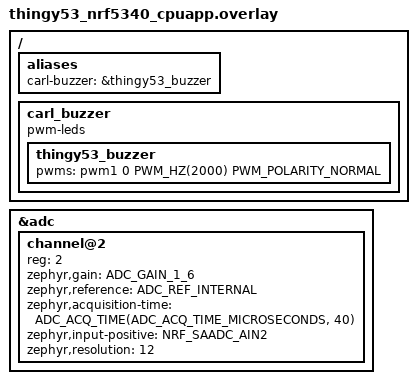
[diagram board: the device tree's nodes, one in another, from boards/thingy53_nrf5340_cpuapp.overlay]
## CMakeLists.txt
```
cmake_minimum_required(VERSION 3.20.0)

find_package(Zephyr REQUIRED HINTS $ENV{ZEPHYR_BASE})

project(carl_node_room LANGUAGES C CXX)

# Per-room environmental sensor node, built around the Nordic Thingy:53.
# Shares the BTHome v2 codec + keystore pattern with the plant-probe node
# (firmware/node-sensor/) so the hub side decodes both with the same path.
# Different sensors_cpp because the onboard chips are different (BME688 +
# BH1749 here vs. BME280 + VEML7700 on the XIAO).
target_sources(app PRIVATE
    src/main.cpp
    src/sensors.cpp
    src/keystore.cpp
    src/bthome_emit.cpp
    src/ui/led.cpp
    src/ui/buzzer.cpp
    # Shared BTHome codec — compiled into the app build, identical to how
    # node-sensor pulls it in.
    ../common/bthome/bthome.cpp
    ../common/bthome/bthome_decode.cpp
    ../common/bthome/aes_ccm.cpp
)

target_include_directories(app PRIVATE
    src
    ../common
    ../common/bthome
)
```

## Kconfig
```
source "Kconfig.zephyr"

menu "Project-Carl room node"

config CARL_ROOM_SAMPLE_INTERVAL_SEC
    int "Sample + broadcast interval (s)"
    default 30
    range 10 600
    help
        How often the room node samples its sensors and emits a BTHome
        advertisement. Default 30 s is bring-up-friendly; production rooms
        with stable conditions can extend this to 5–10 minutes. T/H/P/lux
        change on minute timescales so faster cadence is wasteful.

config CARL_ROOM_BATTERY_LOW_PCT
    int "Battery-low RGB warning threshold (%)"
    default 15
    range 0 100
    help
        Below this level, a successful broadcast blinks amber instead of
        green so a glance at the node signals "needs a charge" without
        checking the dashboard. Matches the hub's default battery_low_pct
        calibration value for consistency.

endmenu
```

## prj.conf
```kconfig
# Carl room-node firmware on the Nordic Thingy:53.
#
# Mirrors firmware/node-sensor/prj.conf wherever it can (BT broadcaster,
# settings/NVS, mbedtls) so the hub decodes both nodes with the same code
# path. Where it differs: enables the Thingy:53's onboard BME688 + BH1749
# sensors, and skips the BME280 / VEML7700 drivers used by the XIAO probe.

# --- Bluetooth (broadcaster only — never connects, just emits BTHome ads) ---
CONFIG_BT=y
CONFIG_BT_PERIPHERAL=y
CONFIG_BT_BROADCASTER=y
CONFIG_BT_DEVICE_NAME="carl-room"
CONFIG_BT_DEVICE_NAME_DYNAMIC=y

# --- Sensors ---
CONFIG_I2C=y
CONFIG_ADC=y
CONFIG_GPIO=y
CONFIG_SENSOR=y
CONFIG_BME680=y          # Zephyr's bme680 driver covers the BME688 part on Thingy:53
CONFIG_BH1749=y          # NCS driver for the Rohm BH1749 RGB/ambient light sensor

# --- Persistence (AES key + counter via settings_nvs) ---
CONFIG_FLASH=y
CONFIG_FLASH_PAGE_LAYOUT=y
CONFIG_FLASH_MAP=y
CONFIG_NVS=y
CONFIG_SETTINGS=y
CONFIG_SETTINGS_NVS=y

# --- RNG for AES key generation on first boot ---
CONFIG_ENTROPY_GENERATOR=y

# --- mbedtls (AES-CCM-128 for BTHome encryption) ---
CONFIG_MBEDTLS=y
CONFIG_MBEDTLS_BUILTIN=y
CONFIG_MBEDTLS_ENABLE_HEAP=y
CONFIG_MBEDTLS_HEAP_SIZE=4096
CONFIG_MBEDTLS_CIPHER_AES_ENABLED=y
CONFIG_MBEDTLS_CIPHER_CCM_ENABLED=y

# --- C++17 to match the shared firmware/common headers ---
CONFIG_CPP=y
CONFIG_STD_CPP17=y
CONFIG_CPP_MAIN=y
CONFIG_LIB_CPLUSPLUS=y
CONFIG_GLIBCXX_LIBCPP=y
CONFIG_NEWLIB_LIBC=y
CONFIG_NEWLIB_LIBC_FLOAT_PRINTF=y

# --- PWM (buzzer on pwm1 + RGB LED on pwm0) ---
CONFIG_PWM=y

# --- Float support for printk (BME688 / BH1749 readings) ---
CONFIG_CBPRINTF_FP_SUPPORT=y

# --- Logging (off by default to save power; flip to y temporarily with
# CONFIG_BT_LOG_LEVEL_DBG=y to diagnose BT host issues during bring-up.) ---
CONFIG_LOG=n
CONFIG_PRINTK=y
```

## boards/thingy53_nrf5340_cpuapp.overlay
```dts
/* Devicetree overlay for the Thingy:53 room node.
 *
 * The board DTS already defines the RGB LED (pwm0 channels 0-2), the buzzer
 * PWM peripheral (pwm1 on P1.15), and a `vbatt` voltage-divider node for the
 * onboard Li-Po (io-channels = <&adc 2>, 1.5M/180k, power-gpios P0.16). This
 * overlay adds:
 *   - the buzzer-as-pwm-led node (grabbed via DT_ALIAS in firmware), and
 *   - the SAADC channel@2 config the vbatt divider needs (the board declares
 *     the divider but not the channel). Channel reg 2 → AIN2 (P0.06), matching
 *     Nordic's `<&adc 2>` reference. The divided Li-Po sits well under the
 *     gain-1/6 / 0.6V-ref full-scale; the 40us acquisition covers the high
 *     divider source impedance.
 */

#include <zephyr/dt-bindings/adc/adc.h>
#include <zephyr/dt-bindings/adc/nrf-adc.h>

/ {
    aliases {
        carl-buzzer = &thingy53_buzzer;
    };

    carl_buzzer: carl_buzzer {
        compatible = "pwm-leds";
        thingy53_buzzer: thingy53_buzzer {
            pwms = <&pwm1 0 PWM_HZ(2000) PWM_POLARITY_NORMAL>;
        };
    };
};

&adc {
    #address-cells = <1>;
    #size-cells = <0>;
    status = "okay";

    channel@2 {
        reg = <2>;
        zephyr,gain = "ADC_GAIN_1_6";
        zephyr,reference = "ADC_REF_INTERNAL";
        zephyr,acquisition-time = <ADC_ACQ_TIME(ADC_ACQ_TIME_MICROSECONDS, 40)>;
        zephyr,input-positive = <NRF_SAADC_AIN2>;
        zephyr,resolution = <12>;
    };
};
```

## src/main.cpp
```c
// Project-Carl — room-monitor node entry point on the Nordic Thingy:53.
//
// Broadcasts T/H/P/lux/battery via BTHome v2 every CARL_ROOM_SAMPLE_INTERVAL_SEC
// seconds. One per room — the hub joins each plant probe's soil reading with
// the room's environment when serving /api/nodes (#16 in the roadmap).
//
// Boot sequence:
//   1. Init sensors + keystore + BT
//   2. Nokia chime on the piezo buzzer + rainbow LED sweep (combined)
//   3. Print MAC + AES key to USB CDC console
//   4. Green LED flash on every successful broadcast, red on failure

#include <zephyr/bluetooth/bluetooth.h>
#include <zephyr/kernel.h>
#include <zephyr/settings/settings.h>
#include <zephyr/sys/printk.h>

#include "bthome_emit.h"
#include "keystore.h"
#include "sensors.h"
#include "ui/buzzer.h"
#include "ui/led.h"

#ifndef CONFIG_CARL_ROOM_SAMPLE_INTERVAL_SEC
#define CONFIG_CARL_ROOM_SAMPLE_INTERVAL_SEC 30
#endif
#ifndef CONFIG_CARL_ROOM_BATTERY_LOW_PCT
#define CONFIG_CARL_ROOM_BATTERY_LOW_PCT 15
#endif

namespace {

const char* airQualityStr(carl::room::sensors::AirQuality aq) {
    using AQ = carl::room::sensors::AirQuality;
    switch (aq) {
        case AQ::kGood:     return "good";
        case AQ::kModerate: return "moderate";
        case AQ::kPoor:     return "poor";
        default:            return "unknown";
    }
}

// Combined boot animation: Nokia tune + rainbow LED sweep.
// Each note of the 13-note tune gets a different colour from the spectrum.
void bootLightShow() {
    struct Step { uint16_t hz; uint16_t ms; uint8_t r, g, b; };
    static constexpr Step kSteps[] = {
        {659, 130, 255,   0,   0},  // E5  — Red
        {587, 130, 255, 100,   0},  // D5  — Orange
        {370, 260, 255, 255,   0},  // F#4 — Yellow
        {415, 260,   0, 255,   0},  // G#4 — Green
        {554, 130,   0, 255, 128},  // C#5 — Spring
        {494, 130,   0, 255, 255},  // B4  — Cyan
        {294, 260,   0, 128, 255},  // D4  — Azure
        {330, 260,   0,   0, 255},  // E4  — Blue
        {494, 130, 128,   0, 255},  // B4  — Violet
        {440, 130, 255,   0, 255},  // A4  — Magenta
        {554, 260, 255,   0, 128},  // C#5 — Rose
        {659, 260, 255, 200, 200},  // E5  — Salmon
        {440, 520, 255, 255, 255},  // A4  — White (finale)
    };

    for (const auto& s : kSteps) {
        carl::room::ui::led::setRGB(s.r, s.g, s.b);
        carl::room::ui::buzzer::tone(s.hz, s.ms);
        k_msleep(20);  // note articulation gap
    }
    carl::room::ui::led::off();
}

void printCredentials() {
    // Always print MAC (not secret). Always print key during bring-up so
    // the user can grab it after any reset — not just first boot. Gate
    // behind a Kconfig flag when shipping production builds.
    bt_addr_le_t addr{};
    size_t addr_count = 1;
    bt_id_get(&addr, &addr_count);
    if (addr_count == 1) {
        const auto* m = addr.a.val;
        printk("\n============================================\n");
        printk("room: MAC  %02X:%02X:%02X:%02X:%02X:%02X\n",
               m[5], m[4], m[3], m[2], m[1], m[0]);
    }
    char hex[33];
    carl::keystore::keyHex(hex);
    printk("room: KEY  %s\n", hex);
    printk("============================================\n\n");
}

void boot() {
    settings_subsys_init();
    settings_load();

    // --- Sensors ---
    if (!carl::room::sensors::init()) {
        printk("room: no sensors initialised — broadcasts will only carry battery\n");
    }

    // --- Keystore ---
    if (!carl::keystore::init()) {
        printk("room: keystore_init failed\n");
    }

    // --- UI ---
    carl::room::ui::led::init();
    carl::room::ui::buzzer::init();

    // --- Bluetooth ---
    if (bt_enable(nullptr) != 0) {
        printk("room: bt_enable failed\n");
        carl::room::ui::buzzer::errorBeep();
        carl::room::ui::led::flashRed(500);
    }
    carl::room::bthome_emit::init();

    // --- Boot animation: Nokia chime + rainbow LED ---
    bootLightShow();

    // --- Credentials (always printed during bring-up) ---
    printCredentials();
}

}  // namespace

int main(void) {
    boot();

    uint32_t sample_no = 0;
    while (true) {
        carl::room::sensors::Sample s{};
        carl::room::sensors::sample(&s);

        printk("room sample #%u: T=%.1fC H=%.0f%% P=%.1fhPa lux=%.0f "
               "gas=%uohm(%s) bat=%u%% (%umV)\n",
               static_cast<unsigned>(sample_no),
               s.temp_ok      ? static_cast<double>(s.temperature_c)   : 0.0,
               s.humidity_ok  ? static_cast<double>(s.humidity_pct)    : 0.0,
               s.pressure_ok  ? static_cast<double>(s.pressure_hpa)   : 0.0,
               s.lux_ok       ? static_cast<double>(s.illuminance_lux) : 0.0,
               static_cast<unsigned>(s.gas_resistance_ohm),
               airQualityStr(s.air_quality),
               static_cast<unsigned>(s.battery_pct),
               static_cast<unsigned>(carl::room::sensors::batteryMv()));

        if (carl::room::bthome_emit::broadcastOnce(s)) {
            // Layer status alerts onto the success blink so a glance at the
            // node signals "needs attention" without checking the dashboard.
            // Poor air takes priority (rarer, more actionable); battery-low
            // is the common case; otherwise plain green — same idea as the
            // plant node's severity blink.
            using AQ = carl::room::sensors::AirQuality;
            const bool battery_low = s.battery_pct > 0
                                    && s.battery_pct <= CONFIG_CARL_ROOM_BATTERY_LOW_PCT;
            if (s.air_quality == AQ::kPoor) {
                carl::room::ui::led::blinkStatus(140, 0, 200, 2);  // 2x purple — poor air
            } else if (battery_low) {
                carl::room::ui::led::blinkStatus(255, 140, 0, 1);  // 1x amber — battery low
            } else {
                carl::room::ui::led::flashGreen();  // all clear
            }
        } else {
            printk("room: broadcast failed\n");
            carl::room::ui::led::flashRed();     // error — red flash
            carl::room::ui::buzzer::errorBeep();
        }

        ++sample_no;
        k_sleep(K_SECONDS(CONFIG_CARL_ROOM_SAMPLE_INTERVAL_SEC));
    }
    return 0;
}
```

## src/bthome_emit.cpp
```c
#include "bthome_emit.h"

#include <cstring>

#include <zephyr/bluetooth/addr.h>
#include <zephyr/bluetooth/bluetooth.h>
#include <zephyr/kernel.h>
#include <zephyr/sys/printk.h>

#include "bthome.h"
#include "keystore.h"

namespace carl::room::bthome_emit {

namespace {

uint8_t g_mac_le[6] = {0};

// How long to broadcast each cycle. Long enough that the hub's passive scan
// (default ~11.25 ms / 11.25 ms = 100 % duty) catches it many times over.
constexpr int kBroadcastMs = 200;

void readMacLe() {
    bt_addr_le_t addr{};
    size_t count = 1;
    bt_id_get(&addr, &count);
    if (count == 1) std::memcpy(g_mac_le, addr.a.val, 6);
}

}  // namespace

bool init() {
    // bt_enable() is called from main; we can read identity here.
    readMacLe();
    return true;
}

bool broadcastOnce(const carl::room::sensors::Sample& s) {
    carl::bthome::Builder b;
    b.addPacketId(static_cast<uint8_t>(carl::keystore::nextCounter() & 0xFF));
    b.addBattery(s.battery_pct);

    if (s.temp_ok)     b.addTemperature(s.temperature_c);
    if (s.humidity_ok) b.addHumidity(s.humidity_pct);
    if (s.pressure_ok) b.addPressure(s.pressure_hpa);
    if (s.lux_ok)      b.addIlluminance(s.illuminance_lux);

    if (!b.ok()) return false;

    uint8_t svc[carl::bthome::kMaxPlaintext + 11];
    size_t  svc_len = 0;
    if (!b.buildEncrypted(svc, sizeof(svc), &svc_len,
                          carl::keystore::key(), g_mac_le,
                          carl::keystore::nextCounter())) {
        return false;
    }

    // BTHome v2 service data only — no BT_DATA_FLAGS. NCS's legacy-adv path
    // rejects the flags-plus-svc-data pair with -EINVAL, and BTHome scanners
    // only key off the service-data UUID 0xFCD2. See firmware/node-sensor/
    // src/bthome_emit.cpp for the long story behind this.
    const struct bt_data ad[] = {
        BT_DATA(BT_DATA_SVC_DATA16, svc, svc_len),
    };

    // BT_LE_ADV_OPT_USE_IDENTITY is required because we don't enable
    // CONFIG_BT_PRIVACY — without it Zephyr can't generate the RPA it
    // would otherwise want to advertise with and bt_le_adv_start returns
    // -EINVAL on every call. Using the device's static random identity
    // address is what we want anyway: stable across reboots so the hub's
    // MAC↔key map keeps working.
    struct bt_le_adv_param param = BT_LE_ADV_PARAM_INIT(
        BT_LE_ADV_OPT_USE_IDENTITY,
        BT_GAP_ADV_FAST_INT_MIN_2,
        BT_GAP_ADV_FAST_INT_MAX_2,
        /*peer=*/nullptr);
    int rc = bt_le_adv_start(&param, ad, ARRAY_SIZE(ad), nullptr, 0);
    if (rc != 0) {
        printk("bt_le_adv_start failed: %d\n", rc);
        return false;
    }
    k_msleep(kBroadcastMs);
    bt_le_adv_stop();
    return true;
}

}  // namespace carl::room::bthome_emit
```

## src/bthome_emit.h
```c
// Build + transmit one BTHome v2 advertisement per sample cycle.
//
// Room node ad fits in a single legacy-AD cycle:
//   packet_id + battery + T + H + P + lux = 18 bytes plaintext
//   + 11 bytes encryption overhead = 29 bytes service data
//   + 2 bytes AD struct header (length + type) = 31 bytes total — at the
//   legacy non-connectable AD ceiling. Adding gas/VOC would require either
//   two-cycle rotation (like firmware/node-sensor/) or extended advertising.

#pragma once

#include "sensors.h"

namespace carl::room::bthome_emit {

bool init();

// Encode one BTHome v2 advertisement and broadcast it for ~200 ms.
// Returns true on success; on failure, prints why to the console.
bool broadcastOnce(const carl::room::sensors::Sample& s);

}  // namespace carl::room::bthome_emit
```

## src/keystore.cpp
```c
#include "keystore.h"

#include <cstring>

#include <zephyr/kernel.h>
#include <zephyr/random/random.h>
#include <zephyr/settings/settings.h>
#include <zephyr/sys/printk.h>

namespace carl::keystore {

namespace {

// Each major settings handler gets its OWN root subtree so Zephyr's
// settings_parse_and_lookup() can route entries unambiguously.
// (When multiple handlers share a root, only the first-linked one gets
// invoked — every other handler's data silently fails to load. That
// regenerated the AES key on every reset before the split.)
constexpr const char* kKeyPath     = "carl_keys/key";
constexpr const char* kCounterPath = "carl_keys/counter";

// Persist the counter to flash every N broadcasts. Lower wears flash faster;
// higher means more counters get re-used after an unclean reset (which is
// safe — the hub rejects non-increasing counters, so a node will simply skip
// ahead by the checkpoint window after reboot).
constexpr uint32_t kCounterCheckpointEvery = 64;

uint8_t   g_key[16];
bool      g_have_key = false;
bool      g_fresh    = false;
uint32_t  g_counter  = 0;
uint32_t  g_counter_persisted = 0;

int settingsLoadCb(const char* name, size_t len, settings_read_cb read_cb,
                   void* cb_arg) {
    const char* next = nullptr;
    int name_len = settings_name_next(name, &next);

    if (name_len == 3 && std::strncmp(name, "key", 3) == 0 && len == sizeof(g_key)) {
        if (read_cb(cb_arg, g_key, sizeof(g_key)) == sizeof(g_key)) {
            g_have_key = true;
        }
        return 0;
    }
    if (name_len == 7 && std::strncmp(name, "counter", 7) == 0
        && len == sizeof(g_counter)) {
        read_cb(cb_arg, &g_counter_persisted, sizeof(g_counter_persisted));
        // Skip ahead a checkpoint window so we never reuse a counter after an
        // unclean reset.
        g_counter = g_counter_persisted + kCounterCheckpointEvery;
        return 0;
    }
    return 0;
}

SETTINGS_STATIC_HANDLER_DEFINE(carl_keystore, "carl_keys",
                               /*get=*/nullptr,
                               /*set=*/settingsLoadCb,
                               /*commit=*/nullptr,
                               /*export=*/nullptr);

void persistCounter(uint32_t v) {
    settings_save_one(kCounterPath, &v, sizeof(v));
    g_counter_persisted = v;
}

}  // namespace

bool init() {
    if (!g_have_key) {
        // First boot: generate fresh key.
        sys_rand_get(g_key, sizeof(g_key));
        if (settings_save_one(kKeyPath, g_key, sizeof(g_key)) != 0) return false;
        g_have_key = true;
        g_fresh    = true;
        persistCounter(0);
    }
    return true;
}

const uint8_t* key() { return g_key; }
bool isFreshKey() { return g_fresh; }

void keyHex(char out[33]) {
    static const char* h = "0123456789ABCDEF";
    for (int i = 0; i < 16; ++i) {
        out[i * 2 + 0] = h[(g_key[i] >> 4) & 0x0F];
        out[i * 2 + 1] = h[g_key[i] & 0x0F];
    }
    out[32] = '\0';
}

uint32_t nextCounter() {
    const uint32_t c = g_counter++;
    if (c - g_counter_persisted >= kCounterCheckpointEvery) {
        persistCounter(g_counter);
    }
    return c;
}

}  // namespace carl::keystore
```

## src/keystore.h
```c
// AES-CCM key + monotonic counter for BTHome v2 broadcasts.
//
// The 16-byte key is generated from the hardware RNG on first boot and
// persisted to NVS via the settings subsystem. The hub gets the key once via
// out-of-band provisioning (OLED display on the display profile, or via the
// connectable calibration window on the cheap profile). The 4-byte counter
// increments per advertisement and is checkpointed to NVS periodically.

#pragma once

#include <cstdint>

namespace carl::keystore {

// Initialize the settings subsystem, load (or first-boot generate) the key
// and counter. Must be called once after settings_subsys_init() / settings_load().
// Returns true on success.
bool init();

// Pointer to the 16-byte key. Stable until reboot.
const uint8_t* key();

// Whether the key was just generated this boot — caller should display it.
bool isFreshKey();

// Render the key as a 32-char uppercase hex string into out (>= 33 bytes).
void keyHex(char out[33]);

// Get the next counter value to use for an advertisement. Bumps + may
// checkpoint to NVS.
uint32_t nextCounter();

}  // namespace carl::keystore
```

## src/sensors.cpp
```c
#include "sensors.h"

#include <zephyr/device.h>
#include <zephyr/devicetree.h>
#include <zephyr/drivers/adc.h>
#include <zephyr/drivers/adc/voltage_divider.h>
#include <zephyr/drivers/gpio.h>
#include <zephyr/drivers/sensor.h>
#include <zephyr/kernel.h>
#include <zephyr/sys/printk.h>

namespace carl::room::sensors {

namespace {

// Both sensors are already declared in the Thingy:53 board DTS — we just
// grab the device handles by compatible string. BME688 uses Zephyr's
// bme680 driver (the chips are register-compatible on the I²C side).
const struct device* g_bme = DEVICE_DT_GET_ANY(bosch_bme680);
const struct device* g_bh  = DEVICE_DT_GET_ANY(rohm_bh1749);

// Onboard Li-Po monitor: the board's `vbatt` voltage-divider node (1.5M/180k
// on AIN2, gated by P0.16). VOLTAGE_DIVIDER_DT_SPEC_GET pulls the ADC channel
// + the divider ratio straight from devicetree, so the scaling math comes
// from the DTS rather than hardcoded constants.
const struct voltage_divider_dt_spec g_vbatt =
    VOLTAGE_DIVIDER_DT_SPEC_GET(DT_PATH(vbatt));
const struct gpio_dt_spec g_vbatt_power =
    GPIO_DT_SPEC_GET(DT_PATH(vbatt), power_gpios);

uint16_t g_battery_mv = 0;

// Read the onboard Li-Po in millivolts. Enables the divider, samples AIN2,
// scales by the DTS divider ratio, then disables the divider to stop the
// ~25uA leakage. Returns 0 on failure.
uint16_t readBatteryMv() {
    if (!adc_is_ready_dt(&g_vbatt.port)) return 0;
    if (adc_channel_setup_dt(&g_vbatt.port) != 0) return 0;

    // Enable the divider (power-gpios) and let the high-impedance node settle.
    if (gpio_is_ready_dt(&g_vbatt_power)) {
        gpio_pin_configure_dt(&g_vbatt_power, GPIO_OUTPUT_ACTIVE);
        k_msleep(2);
    }

    int16_t buf = 0;
    struct adc_sequence seq = {};
    (void)adc_sequence_init_dt(&g_vbatt.port, &seq);
    seq.buffer = &buf;
    seq.buffer_size = sizeof(buf);
    seq.calibrate = true;

    // High source impedance: a single acquisition undersamples (reads low and
    // jitters). Burst-read so the sample-and-hold converges, drop the first 8
    // warm-up reads, then average the settled tail. Same fix as the XIAO probe.
    uint16_t out_mv = 0;
    int32_t acc = 0;
    int n = 0;
    bool read_ok = true;
    for (int i = 0; i < 16; ++i) {
        if (adc_read(g_vbatt.port.dev, &seq) != 0) { read_ok = false; break; }
        if (i >= 8) { acc += buf; ++n; }
    }
    if (read_ok && n > 0) {
        int32_t mv = acc / n;
        if (adc_raw_to_millivolts_dt(&g_vbatt.port, &mv) == 0
            && voltage_divider_scale_dt(&g_vbatt, &mv) == 0
            && mv > 2000 && mv < 5000) {
            out_mv = static_cast<uint16_t>(mv);
        }
    }

    if (gpio_is_ready_dt(&g_vbatt_power)) {
        gpio_pin_configure_dt(&g_vbatt_power, GPIO_OUTPUT_INACTIVE);
    }
    return out_mv;
}

// LiPo discharge curve, linear over the useful 3.30 V (empty) → 4.20 V (full)
// span — same approximation the XIAO plant probe uses.
uint8_t batteryPctFromMv(uint16_t mv) {
    if (mv == 0)    return 0;
    if (mv >= 4200) return 100;
    if (mv <= 3300) return 0;
    return static_cast<uint8_t>((mv - 3300) * 100u / 900u);
}

// Photopic-luminosity conversion for the BH1749. The chip outputs raw
// 16-bit RGB+IR counts; the green channel best matches the CIE V(λ)
// human-eye response. Rohm's app note gives an approximate constant of
// ~1 lux per 19 counts at gain=1×, integration=160 ms — the driver
// defaults. Plenty accurate for "is this plant getting bright/medium/low
// light" buckets.
constexpr float kBh1749GreenToLux = 1.0f / 19.0f;

// Rolling-baseline air-quality heuristic. BME688 gas resistance rises with
// cleaner air; without BSEC there's no calibrated absolute scale, so we
// track the highest resistance seen ("cleanest air observed") and classify
// the current reading relative to it. The baseline only ever rises
// immediately (a cleaner moment is trustworthy right away) and decays
// slowly on every sample otherwise (~0.1%/sample — hours to fully
// re-baseline down), so a new lasting steady-state — windows opened,
// incense burned — doesn't get stuck flagged "poor" forever.
float g_gas_baseline_ohm = 0.0f;

AirQuality classifyAirQuality(uint32_t gas_ohm) {
    if (gas_ohm == 0) return AirQuality::kUnknown;
    const float g = static_cast<float>(gas_ohm);
    if (g_gas_baseline_ohm <= 0.0f) {
        g_gas_baseline_ohm = g;  // first-ever reading seeds the baseline
        return AirQuality::kGood;
    }
    if (g > g_gas_baseline_ohm) {
        g_gas_baseline_ohm = g;
    } else {
        g_gas_baseline_ohm *= 0.999f;
    }
    const float ratio = g / g_gas_baseline_ohm;
    if (ratio >= 0.90f) return AirQuality::kGood;
    if (ratio >= 0.70f) return AirQuality::kModerate;
    return AirQuality::kPoor;
}

}  // namespace

bool init() {
    bool any_ok = false;

    if (g_bme == nullptr) {
        printk("room-sensors: BME688 not present in devicetree\n");
    } else if (!device_is_ready(g_bme)) {
        printk("room-sensors: BME688 device not ready\n");
        g_bme = nullptr;
    } else {
        printk("room-sensors: BME688 ready\n");
        any_ok = true;
    }

    if (g_bh == nullptr) {
        printk("room-sensors: BH1749 not present in devicetree\n");
    } else if (!device_is_ready(g_bh)) {
        printk("room-sensors: BH1749 device not ready\n");
        g_bh = nullptr;
    } else {
        printk("room-sensors: BH1749 ready\n");
        any_ok = true;
    }

    return any_ok;
}

bool sample(Sample* out) {
    *out = Sample{};
    bool any_ok = false;

    if (g_bme != nullptr && sensor_sample_fetch(g_bme) == 0) {
        struct sensor_value v{};
        if (sensor_channel_get(g_bme, SENSOR_CHAN_AMBIENT_TEMP, &v) == 0) {
            out->temperature_c = sensor_value_to_double(&v);
            out->temp_ok = true; any_ok = true;
        }
        if (sensor_channel_get(g_bme, SENSOR_CHAN_HUMIDITY, &v) == 0) {
            out->humidity_pct = sensor_value_to_double(&v);
            out->humidity_ok = true;
        }
        if (sensor_channel_get(g_bme, SENSOR_CHAN_PRESS, &v) == 0) {
            // Zephyr returns kPa; BTHome wants hPa.
            out->pressure_hpa = sensor_value_to_double(&v) * 10.0;
            out->pressure_ok = true;
        }
        // Gas resistance is in ohms. Kept off the BTHome ad for v1 because
        // BTHome 0x13 wants ppb, not raw resistance — accurate conversion
        // needs Bosch's BSEC library which is a proprietary binary blob.
        if (sensor_channel_get(g_bme, SENSOR_CHAN_GAS_RES, &v) == 0) {
            out->gas_resistance_ohm = static_cast<uint32_t>(sensor_value_to_double(&v));
            out->gas_ok = true;
            out->air_quality = classifyAirQuality(out->gas_resistance_ohm);
        }
    }

    if (g_bh != nullptr && sensor_sample_fetch(g_bh) == 0) {
        struct sensor_value g{};
        if (sensor_channel_get(g_bh, SENSOR_CHAN_GREEN, &g) == 0) {
            // sensor_value's val1 holds the integer green count (BH1749 raw).
            const float green_raw = static_cast<float>(g.val1);
            out->illuminance_lux = green_raw * kBh1749GreenToLux;
            out->lux_ok = true; any_ok = true;
        }
    }

    // Real onboard Li-Po reading via the board's vbatt divider. Falls back to
    // 0 % if the ADC/GPIO isn't ready (distinguishes a flat/unknown cell from
    // the old hardcoded 100 %). The per-sample printk in main.cpp shows the
    // raw mV so a wrong AIN mapping is obvious on the bench (expect ~3300-4200).
    const uint16_t mv = readBatteryMv();
    g_battery_mv = mv;
    out->battery_pct = batteryPctFromMv(mv);

    return any_ok;
}

uint16_t batteryMv() { return g_battery_mv; }

}  // namespace carl::room::sensors
```

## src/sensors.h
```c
// Sensor sampling for the Carl room-monitor node (Thingy:53).
//
// Reads the onboard BME688 (T/H/P + gas resistance) and BH1749 (RGB + IR
// → photopic lux), plus the board's VBAT divider for battery state.
// Same Sample shape as firmware/node-sensor/src/sensors.h so the BTHome
// emitter can share code between probe + room variants.

#pragma once

#include <cstdint>

namespace carl::room::sensors {

// Heuristic air-quality bucket derived from BME688 gas resistance, relative
// to a self-learned "cleanest air seen" baseline. NOT a calibrated VOC/IAQ
// value — that needs Bosch's proprietary BSEC library, which this firmware
// doesn't link. Local-feedback only (RGB); deliberately not broadcast over
// BTHome, since mislabeling a heuristic as the wire format's VOC object
// (which expects real µg/m³) would misrepresent the data to Home Assistant.
enum class AirQuality : uint8_t { kUnknown, kGood, kModerate, kPoor };

struct Sample {
    bool     temp_ok;
    float    temperature_c;   // °C — BME688
    bool     humidity_ok;
    float    humidity_pct;    // % — BME688
    bool     pressure_ok;
    float    pressure_hpa;    // hPa — BME688

    bool     lux_ok;
    float    illuminance_lux; // lux — BH1749 green channel × photopic scale

    // BME688 gas resistance in ohms. Higher = cleaner air. Not currently
    // broadcast — wire format wants a proper VOC index in ppb (BTHome 0x13)
    // which BME688 only produces via Bosch's BSEC binary blob. Kept here
    // for future use / OLED debug.
    bool     gas_ok;
    uint32_t gas_resistance_ohm;
    AirQuality air_quality;   // heuristic bucket from gas_resistance_ohm; kUnknown if !gas_ok

    uint8_t  battery_pct;     // 0..100 % — VBAT divider on ADC ch 2
};

// Initialise the onboard sensors. Loud printk on success / failure so the
// USB CDC log makes it obvious when wiring or a driver isn't right.
// Returns true if at least one sensor initialised.
bool init();

// Sample every sensor that initialised. Per-channel *_ok flags indicate
// per-channel success; returns true if at least one channel succeeded.
bool sample(Sample* out);

// Last successful battery voltage in millivolts (0 = not yet read / failed).
uint16_t batteryMv();

}  // namespace carl::room::sensors
```
